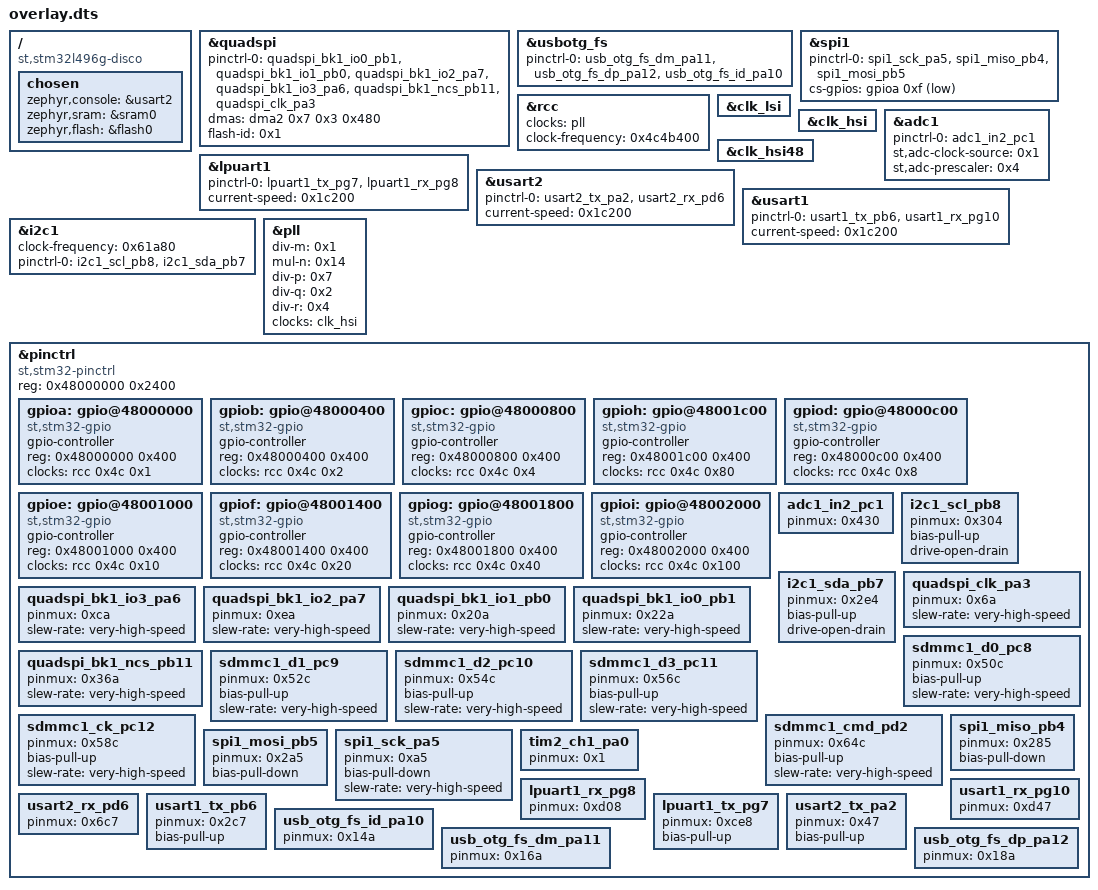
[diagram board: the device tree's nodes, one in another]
/ {
	compatible = "st,stm32l496g-disco";
	chosen {
		zephyr,console = &usart2;
		zephyr,sram = &sram0;
		zephyr,flash = &flash0;
	};
};
&quadspi{
	status = "okay";
	pinctrl-0 = < &quadspi_bk1_io0_pb1 &quadspi_bk1_io1_pb0 &quadspi_bk1_io2_pa7 &quadspi_bk1_io3_pa6 &quadspi_bk1_ncs_pb11 &quadspi_clk_pa3 >;
	pinctrl-names = "default";
	dmas = < &dma2 0x7 0x3 0x480 >;
	dma-names = "tx_rx";
	flash-id = < 0x1 >;
};
&usbotg_fs{
	status = "okay";
	pinctrl-0 = < &usb_otg_fs_dm_pa11 &usb_otg_fs_dp_pa12 &usb_otg_fs_id_pa10 >;
	pinctrl-names = "default";
};
&spi1{
	status = "okay";
	pinctrl-0 = < &spi1_sck_pa5 &spi1_miso_pb4 &spi1_mosi_pb5 >;
	pinctrl-names = "default";
	cs-gpios = < &gpioa 0xf 0x11 >;
};
&rcc{
	clocks = < &pll >;
	clock-frequency = < 0x4c4b400 >;
};
&clk_lsi{
	status = "okay";
};
&clk_hsi{
	status = "okay";
};
&adc1{
	status = "okay";
	pinctrl-0 = < &adc1_in2_pc1 >;
	pinctrl-names = "default";
	st,adc-clock-source = < 0x1 >;
	st,adc-prescaler = < 0x4 >;
};
&lpuart1{
	status = "okay";
	pinctrl-0 = < &lpuart1_tx_pg7 &lpuart1_rx_pg8 >;
	pinctrl-names = "default";
	current-speed = < 0x1c200 >;
};
&clk_hsi48{
	status = "okay";
};
&usart2{
	status = "okay";
	pinctrl-0 = < &usart2_tx_pa2 &usart2_rx_pd6 >;
	pinctrl-names = "default";
	current-speed = < 0x1c200 >;
};
&usart1{
	status = "okay";
	pinctrl-0 = < &usart1_tx_pb6 &usart1_rx_pg10 >;
	pinctrl-names = "default";
	current-speed = < 0x1c200 >;
};
&i2c1{
	clock-frequency = < 0x61a80 >;
	status = "okay";
	pinctrl-0 = < &i2c1_scl_pb8 &i2c1_sda_pb7 >;
	pinctrl-names = "default";
};
&pll{
	status = "okay";
	div-m = < 0x1 >;
	mul-n = < 0x14 >;
	div-p = < 0x7 >;
	div-q = < 0x2 >;
	div-r = < 0x4 >;
	clocks = < &clk_hsi >;
};
&pinctrl{
	compatible = "st,stm32-pinctrl";
	#address-cells = < 0x1 >;
	#size-cells = < 0x1 >;
	reg = < 0x48000000 0x2400 >;
	gpioa: gpio@48000000 {
		compatible = "st,stm32-gpio";
		gpio-controller;
		#gpio-cells = < 0x2 >;
		reg = < 0x48000000 0x400 >;
		clocks = < &rcc 0x4c 0x1 >;
	};
	gpiob: gpio@48000400 {
		compatible = "st,stm32-gpio";
		gpio-controller;
		#gpio-cells = < 0x2 >;
		reg = < 0x48000400 0x400 >;
		clocks = < &rcc 0x4c 0x2 >;
	};
	gpioc: gpio@48000800 {
		compatible = "st,stm32-gpio";
		gpio-controller;
		#gpio-cells = < 0x2 >;
		reg = < 0x48000800 0x400 >;
		clocks = < &rcc 0x4c 0x4 >;
	};
	gpioh: gpio@48001c00 {
		compatible = "st,stm32-gpio";
		gpio-controller;
		#gpio-cells = < 0x2 >;
		reg = < 0x48001c00 0x400 >;
		clocks = < &rcc 0x4c 0x80 >;
	};
	gpiod: gpio@48000c00 {
		compatible = "st,stm32-gpio";
		gpio-controller;
		#gpio-cells = < 0x2 >;
		reg = < 0x48000c00 0x400 >;
		clocks = < &rcc 0x4c 0x8 >;
	};
	gpioe: gpio@48001000 {
		compatible = "st,stm32-gpio";
		gpio-controller;
		#gpio-cells = < 0x2 >;
		reg = < 0x48001000 0x400 >;
		clocks = < &rcc 0x4c 0x10 >;
	};
	gpiof: gpio@48001400 {
		compatible = "st,stm32-gpio";
		gpio-controller;
		#gpio-cells = < 0x2 >;
		reg = < 0x48001400 0x400 >;
		clocks = < &rcc 0x4c 0x20 >;
	};
	gpiog: gpio@48001800 {
		compatible = "st,stm32-gpio";
		gpio-controller;
		#gpio-cells = < 0x2 >;
		reg = < 0x48001800 0x400 >;
		clocks = < &rcc 0x4c 0x40 >;
	};
	gpioi: gpio@48002000 {
		compatible = "st,stm32-gpio";
		gpio-controller;
		#gpio-cells = < 0x2 >;
		reg = < 0x48002000 0x400 >;
		clocks = < &rcc 0x4c 0x100 >;
	};
	adc1_in2_pc1: adc1_in2_pc1 {
		pinmux = < 0x430 >;
	};
	i2c1_scl_pb8: i2c1_scl_pb8 {
		pinmux = < 0x304 >;
		bias-pull-up;
		drive-open-drain;
	};
	i2c1_sda_pb7: i2c1_sda_pb7 {
		pinmux = < 0x2e4 >;
		bias-pull-up;
		drive-open-drain;
	};
	quadspi_clk_pa3: quadspi_clk_pa3 {
		pinmux = < 0x6a >;
		slew-rate = "very-high-speed";
	};
	quadspi_bk1_io3_pa6: quadspi_bk1_io3_pa6 {
		pinmux = < 0xca >;
		slew-rate = "very-high-speed";
	};
	quadspi_bk1_io2_pa7: quadspi_bk1_io2_pa7 {
		pinmux = < 0xea >;
		slew-rate = "very-high-speed";
	};
	quadspi_bk1_io1_pb0: quadspi_bk1_io1_pb0 {
		pinmux = < 0x20a >;
		slew-rate = "very-high-speed";
	};
	quadspi_bk1_io0_pb1: quadspi_bk1_io0_pb1 {
		pinmux = < 0x22a >;
		slew-rate = "very-high-speed";
	};
	quadspi_bk1_ncs_pb11: quadspi_bk1_ncs_pb11 {
		pinmux = < 0x36a >;
		slew-rate = "very-high-speed";
	};
	sdmmc1_d0_pc8: sdmmc1_d0_pc8 {
		pinmux = < 0x50c >;
		bias-pull-up;
		slew-rate = "very-high-speed";
	};
	sdmmc1_d1_pc9: sdmmc1_d1_pc9 {
		pinmux = < 0x52c >;
		bias-pull-up;
		slew-rate = "very-high-speed";
	};
	sdmmc1_d2_pc10: sdmmc1_d2_pc10 {
		pinmux = < 0x54c >;
		bias-pull-up;
		slew-rate = "very-high-speed";
	};
	sdmmc1_d3_pc11: sdmmc1_d3_pc11 {
		pinmux = < 0x56c >;
		bias-pull-up;
		slew-rate = "very-high-speed";
	};
	sdmmc1_ck_pc12: sdmmc1_ck_pc12 {
		pinmux = < 0x58c >;
		bias-pull-up;
		slew-rate = "very-high-speed";
	};
	sdmmc1_cmd_pd2: sdmmc1_cmd_pd2 {
		pinmux = < 0x64c >;
		bias-pull-up;
		slew-rate = "very-high-speed";
	};
	spi1_miso_pb4: spi1_miso_pb4 {
		pinmux = < 0x285 >;
		bias-pull-down;
	};
	spi1_mosi_pb5: spi1_mosi_pb5 {
		pinmux = < 0x2a5 >;
		bias-pull-down;
	};
	spi1_sck_pa5: spi1_sck_pa5 {
		pinmux = < 0xa5 >;
		bias-pull-down;
		slew-rate = "very-high-speed";
	};
	tim2_ch1_pa0: tim2_ch1_pa0 {
		pinmux = < 0x1 >;
	};
	lpuart1_rx_pg8: lpuart1_rx_pg8 {
		pinmux = < 0xd08 >;
	};
	usart1_rx_pg10: usart1_rx_pg10 {
		pinmux = < 0xd47 >;
	};
	usart2_rx_pd6: usart2_rx_pd6 {
		pinmux = < 0x6c7 >;
	};
	usart1_tx_pb6: usart1_tx_pb6 {
		pinmux = < 0x2c7 >;
		bias-pull-up;
	};
	lpuart1_tx_pg7: lpuart1_tx_pg7 {
		pinmux = < 0xce8 >;
		bias-pull-up;
	};
	usart2_tx_pa2: usart2_tx_pa2 {
		pinmux = < 0x47 >;
		bias-pull-up;
	};
	usb_otg_fs_id_pa10: usb_otg_fs_id_pa10 {
		pinmux = < 0x14a >;
	};
	usb_otg_fs_dm_pa11: usb_otg_fs_dm_pa11 {
		pinmux = < 0x16a >;
	};
	usb_otg_fs_dp_pa12: usb_otg_fs_dp_pa12 {
		pinmux = < 0x18a >;
	};
};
